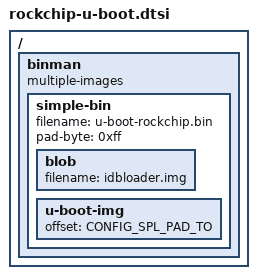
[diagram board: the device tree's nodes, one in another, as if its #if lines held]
/*
****************************************************************************************************************
*= = SPDX-License-Identifier: MIT
*= = Copyright (C) 2015 - 2029. Asytumn Technology Co., Ltd.
*= = Carlyon W. Tung
****************************************************************************************************************
*/

#include <config.h>

/ {
    binman: binman {
        multiple-images;
    };
};

#ifdef CONFIG_SPL
&binman {
    simple-bin {
        filename = "u-boot-rockchip.bin";
        pad-byte = <0xff>;

        blob {
            filename = "idbloader.img";
        };

        u-boot-img {
            offset = <CONFIG_SPL_PAD_TO>;
        };
    };
};
#endif


/*
****************************************************************************************************************
*= = END OF FILE
****************************************************************************************************************
*/


